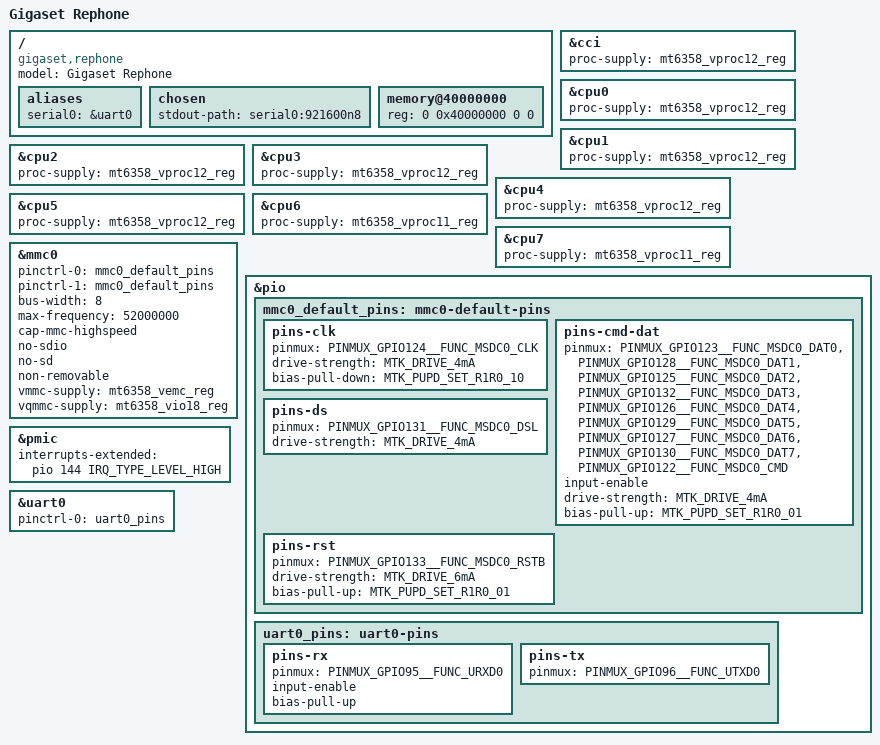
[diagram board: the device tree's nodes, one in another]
// SPDX-License-Identifier: GPL-2.0-only
/dts-v1/;

#include <dt-bindings/gpio/gpio.h>
#include "mt6768.dtsi"
#include "mt6358.dtsi"

/ {
	model = "Gigaset Rephone";
	compatible = "gigaset,rephone", "mediatek,mt6768";

	aliases {
		serial0 = &uart0;
	};

	chosen {
		stdout-path = "serial0:921600n8";
	};

	memory@40000000 {
		device_type = "memory";
		reg = <0 0x40000000 0 0>;
	};
};

&cci {
	proc-supply = <&mt6358_vproc12_reg>;
};

&cpu0 {
	proc-supply = <&mt6358_vproc12_reg>;
};

&cpu1 {
	proc-supply = <&mt6358_vproc12_reg>;
};

&cpu2 {
	proc-supply = <&mt6358_vproc12_reg>;
};

&cpu3 {
	proc-supply = <&mt6358_vproc12_reg>;
};

&cpu4 {
	proc-supply = <&mt6358_vproc12_reg>;
};

&cpu5 {
	proc-supply = <&mt6358_vproc12_reg>;
};

&cpu6 {
	proc-supply = <&mt6358_vproc11_reg>;
};

&cpu7 {
	proc-supply = <&mt6358_vproc11_reg>;
};

&mmc0 {
	pinctrl-0 = <&mmc0_default_pins>;
	pinctrl-1 = <&mmc0_default_pins>;
	pinctrl-names = "default", "state_uhs";
	bus-width = <8>;
	max-frequency = <52000000>;
	cap-mmc-highspeed;
	no-sdio;
	no-sd;
	non-removable;
	vmmc-supply = <&mt6358_vemc_reg>;
	vqmmc-supply = <&mt6358_vio18_reg>;

	status = "okay";
};

&pio {
	mmc0_default_pins: mmc0-default-pins {
		pins-clk {
			pinmux = <PINMUX_GPIO124__FUNC_MSDC0_CLK>;
			drive-strength = <MTK_DRIVE_4mA>;
			bias-pull-down = <MTK_PUPD_SET_R1R0_10>;
		};

		pins-cmd-dat {
			pinmux = <PINMUX_GPIO123__FUNC_MSDC0_DAT0>,
				 <PINMUX_GPIO128__FUNC_MSDC0_DAT1>,
				 <PINMUX_GPIO125__FUNC_MSDC0_DAT2>,
				 <PINMUX_GPIO132__FUNC_MSDC0_DAT3>,
				 <PINMUX_GPIO126__FUNC_MSDC0_DAT4>,
				 <PINMUX_GPIO129__FUNC_MSDC0_DAT5>,
				 <PINMUX_GPIO127__FUNC_MSDC0_DAT6>,
				 <PINMUX_GPIO130__FUNC_MSDC0_DAT7>,
				 <PINMUX_GPIO122__FUNC_MSDC0_CMD>;
			input-enable;
			drive-strength = <MTK_DRIVE_4mA>;
			bias-pull-up = <MTK_PUPD_SET_R1R0_01>;
		};

		pins-ds {
			pinmux = <PINMUX_GPIO131__FUNC_MSDC0_DSL>;
			drive-strength = <MTK_DRIVE_4mA>;
		};

		pins-rst {
			pinmux = <PINMUX_GPIO133__FUNC_MSDC0_RSTB>;
			drive-strength = <MTK_DRIVE_6mA>;
			bias-pull-up = <MTK_PUPD_SET_R1R0_01>;
		};
	};

	uart0_pins: uart0-pins {
		pins-rx {
			pinmux = <PINMUX_GPIO95__FUNC_URXD0>;
			input-enable;
			bias-pull-up;
		};

		pins-tx {
			pinmux = <PINMUX_GPIO96__FUNC_UTXD0>;
		};
	};
};

&pmic {
	interrupts-extended = <&pio 144 IRQ_TYPE_LEVEL_HIGH>;
};

&uart0 {
	pinctrl-0 = <&uart0_pins>;
	pinctrl-names = "default";
	status = "okay";
};
